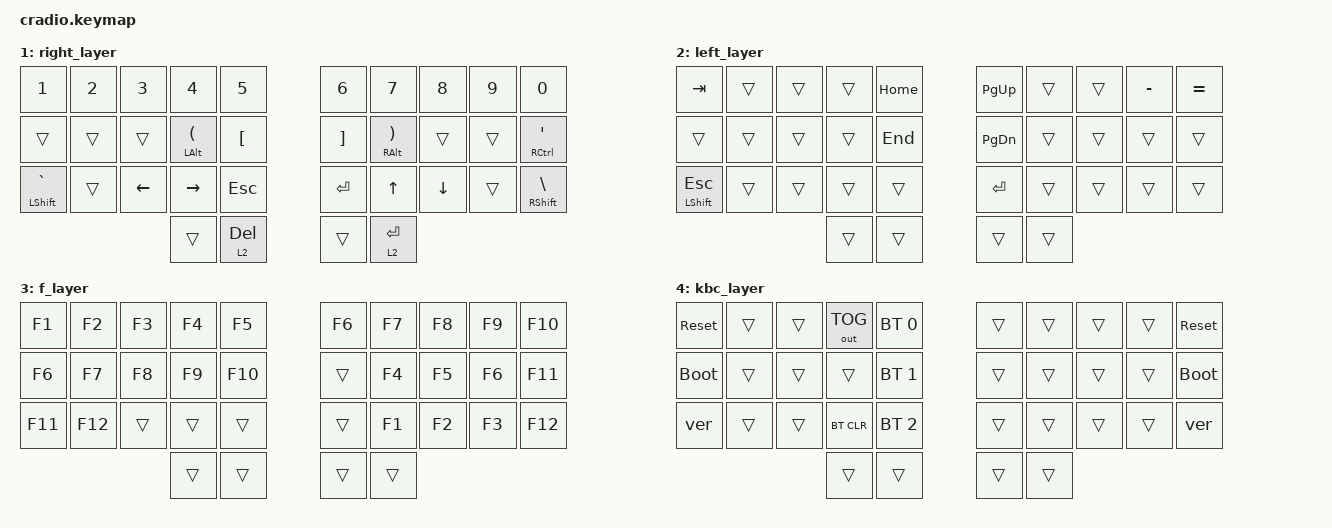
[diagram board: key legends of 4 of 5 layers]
// Copyright (c) 2022 The ZMK Contributors
// SPDX-License-Identifier: MIT

#include <behaviors.dtsi>
#include <dt-bindings/zmk/keys.h>
#include <dt-bindings/zmk/bt.h>
#include <dt-bindings/zmk/outputs.h>

#define YEAR_KEYS(y1, y2) &kp N2 &kp N0 &kp N##y1 &kp N##y2
#define MON_KEYS(m1, m2, m3) &kp m1 &kp m2 &kp m3
#define VER_KEYS(n1, n2) &kp N##n1 &kp N##n2

#define MYEAR YEAR_KEYS(2,5)
#define MMON MON_KEYS(J,A,N)
#define MVER VER_KEYS(0,3)

// Home row mods macro
#define HRML(k1,k2,k3,k4,k5) &ht LCTRL k1  &kp k2  &ht LGUI k3  &ht LALT k4  &kp k5
#define HRMR(k1,k2,k3,k4,k5) &kp k1  &ht RALT k2  &ht RGUI k3  &kp k4  &ht RCTRL k5
#define BRML(k1,k2,k3,k4,k5) &ht LSHIFT k1  &kp k2  &kp k3  &kp k4  &kp k5
#define BRMR(k1,k2,k3,k4,k5) &kp k1  &kp k2  &kp k3  &kp k4  &ht RSHIFT k5

&lt {
    flavor = "balanced";
};

/ {
    behaviors {
        ht: hold_tap {
            label = "hold_tap";
            compatible = "zmk,behavior-hold-tap";
            #binding-cells = <2>;
            flavor = "balanced";
            tapping-term-ms = <220>;
            quick-tap-ms = <150>;
            require-prior-idle-ms = <100>;
            bindings = <&kp>, <&kp>;
        };
        ver: behavior_version {
            compatible = "zmk,behavior-macro";
            #binding-cells = <0>;
            bindings = <&kp N &kp D &kp MINUS MYEAR &kp MINUS MMON &kp MINUS MVER>;
        };
    };

    conditional_layers {
        compatible = "zmk,conditional-layers";
        kbc_layer {
            if-layers = <1 2>;
            then-layer = <4>;
        };
        kbc2_layer {
            if-layers = <2 3>;
            then-layer = <4>;
        };
        kbc3_layer {
            if-layers = <1 3>;
            then-layer = <4>;
        };
    };

    keymap {
        compatible = "zmk,keymap";
        default_layer {
            bindings = <
        //╭──────────┬──────────┬──────────┬──────────┬──────────╮   ╭──────────┬──────────┬──────────┬──────────┬──────────╮
        //│  Q       │  W       │  E       │  R       │  T       │   │  Y       │  U       │  I       │  O       │  P       │
            &kp Q      &kp W      &kp E      &kp R      &kp T          &kp Y      &kp U      &kp I      &kp O      &kp P
        //├──────────┼──────────┼──────────┼──────────┼──────────┤   ├──────────┼──────────┼──────────┼──────────┼──────────┤
        //│  A       │  S       │  D       │  F       │  G       │   │  H       │  J       │  K       │  L       │ ; :      │
            HRML(A,        S,         D,         F,        G)           HRMR(H,      J,        K,         L,        SEMI)
        //├──────────┼──────────┼──────────┼──────────┼──────────┤   ├──────────┼──────────┼──────────┼──────────┼──────────┤
        //│  Z       │  X       │  C       │  V       │  B       │   │  N       │  M       │ , <      │ . >      │ / ?      │
            BRML(Z,       X,        C,          V,         B)          BRMR(N,      M,        COMMA,      DOT,       FSLH)
        //╰──────────┴──────────┴──────────┼──────────┼──────────┤   ├──────────┼──────────┼──────────┴──────────┴──────────╯
                                            &lt 3 TAB   &lt 2 BSPC    &lt 1 SPACE &lt 3 ENTER
        //                                 ╰──────────┴──────────╯   ╰──────────┴──────────╯
            >;
        };

        right_layer {
            bindings = <
        //╭──────────┬──────────┬──────────┬──────────┬──────────╮   ╭──────────┬──────────┬──────────┬──────────┬──────────╮
        //│ 1        │  2       │  3       │  4       │  5       │   │ 6        │ 7        │ 8        │ 9        │  0       │
            &kp N1     &kp N2     &kp N3     &kp N4     &kp N5        &kp N6     &kp N7     &kp N8     &kp N9     &kp N0
        //├──────────┼──────────┼──────────┼──────────┼──────────┤   ├──────────┼──────────┼──────────┼──────────┼──────────┤
        //│          │          │          │  (       │  [       │   │ ]        │ )        │          │          │' "       │
            &trans    &trans     &trans    &ht LALT LPAR &kp LBKT      &kp RBKT &ht RALT RPAR  &trans    &trans  &ht RCTRL SQT
        //├──────────┼──────────┼──────────┼──────────┼──────────┤   ├──────────┼──────────┼──────────┼──────────┼──────────┤
        //│ ` ~      │          │ LEFT     │ RIGHT    │ Esc      │   │ Enter    │ UP       │ DOWN     │          │ \ |      │
          &ht LSHIFT GRAVE &trans  &kp LEFT   &kp RIGHT   &kp ESC      &kp ENTER  &kp UP     &kp DOWN  &trans     &ht RSHIFT BSLH
        //╰──────────┴──────────┴──────────┼──────────┼──────────┤   ├──────────┼──────────┼──────────┴──────────┴──────────╯
                                             &trans    &lt 2 DEL         &trans   &lt 2 ENTER
        //                                 ╰──────────┴──────────╯   ╰──────────┴──────────╯
            >;
        };

        left_layer {
            bindings = <
        //╭──────────┬──────────┬──────────┬──────────┬──────────╮   ╭──────────┬──────────┬──────────┬──────────┬──────────╮
        //│ TAB      │          │          │          │ HOME     │   │ PAGE UP  │          │          │  - _     │  = +     │
           &kp TAB    &trans     &trans     &trans     &kp HOME       &kp PG_UP  &trans     &trans     &kp MINUS   &kp EQUAL
        //├──────────┼──────────┼──────────┼──────────┼──────────┤   ├──────────┼──────────┼──────────┼──────────┼──────────┤
        //│          │          │          │          │  END     │   │ PAGE DOWN│          │          │          │          │
            &trans    &trans     &trans     &trans     &kp END       &kp PG_DN   &trans     &trans     &trans     &trans
        //├──────────┼──────────┼──────────┼──────────┼──────────┤   ├──────────┼──────────┼──────────┼──────────┼──────────┤
        //│  ESC     │          │          │          │          │   │  ENTER   │          │          │          │          │
          &ht LSHIFT ESC  &trans   &trans     &trans     &trans         &kp ENTER   &trans    &trans     &trans     &trans
        //╰──────────┴──────────┴──────────┼──────────┼──────────┤   ├──────────┼──────────┼──────────┴──────────┴──────────╯
                                             &trans     &trans         &trans     &trans
        //                                 ╰──────────┴──────────╯   ╰──────────┴──────────╯
            >;
        };

        f_layer {
            bindings = <
        //╭──────────┬──────────┬──────────┬──────────┬──────────╮   ╭──────────┬──────────┬──────────┬──────────┬──────────╮
        //│ F1       │ F2       │ F3       │ F4       │ F5       │   │ F6       │ F7       │ F8       │ F9       │ F10      │
           &kp F1     &kp F2     &kp F3     &kp F4     &kp F5         &kp F6     &kp F7     &kp F8     &kp F9     &kp F10
        //├──────────┼──────────┼──────────┼──────────┼──────────┤   ├──────────┼──────────┼──────────┼──────────┼──────────┤
        //│ F6       │ F7       │ F8       │ F9       │ F10      │   │          │ F4       │ F5       │ F6       │ F11      │
           &kp F6     &kp F7     &kp F8     &kp F9     &kp F10        &trans     &kp F4     &kp F5     &kp F6     &kp F11
        //├──────────┼──────────┼──────────┼──────────┼──────────┤   ├──────────┼──────────┼──────────┼──────────┼──────────┤
        //│ F11      │  F12     │          │          │          │   │          │ F1       │ F2       │ F3       │ F12      │
            &kp F11    &kp F12    &trans    &trans     &trans         &trans     &kp F1     &kp F2     &kp F3     &kp F12
        //╰──────────┴──────────┴──────────┼──────────┼──────────┤   ├──────────┼──────────┼──────────┴──────────┴──────────╯
                                             &trans     &trans         &trans     &trans
        //                                 ╰──────────┴──────────╯   ╰──────────┴──────────╯
            >;
        };

        kbc_layer {
            bindings = <
        //╭──────────┬──────────┬──────────┬──────────┬──────────╮   ╭──────────┬──────────┬──────────┬──────────┬──────────╮
        //│ RESET    │          │          │TOG BT/USB│PROFILE 0 │   │          │          │          │          │  RESET   │
           &sys_reset  &trans     &trans   &out OUT_TOG &bt BT_SEL 0   &trans     &trans     &trans     &trans    &sys_reset
        //├──────────┼──────────┼──────────┼──────────┼──────────┤   ├──────────┼──────────┼──────────┼──────────┼──────────┤
        //│BOOTLOADER│          │          │          │PROFILE 1 │   │          │          │          │          │BOOTLOADER│
          &bootloader  &trans     &trans     &trans    &bt BT_SEL 1    &trans     &trans     &trans     &trans    &bootloader
        //├──────────┼──────────┼──────────┼──────────┼──────────┤   ├──────────┼──────────┼──────────┼──────────┼──────────┤
        //│          │          │          │ CLEAR BT │PROFILE 2 │   │          │          │          │          │          │
            &ver       &trans     &trans    &bt BT_CLR &bt BT_SEL 2    &trans     &trans     &trans     &trans     &ver
        //╰──────────┴──────────┴──────────┼──────────┼──────────┤   ├──────────┼──────────┼──────────┴──────────┴──────────╯
                                             &trans     &trans         &trans     &trans
        //                                 ╰──────────┴──────────╯   ╰──────────┴──────────╯
            >;
        };
    };
};
